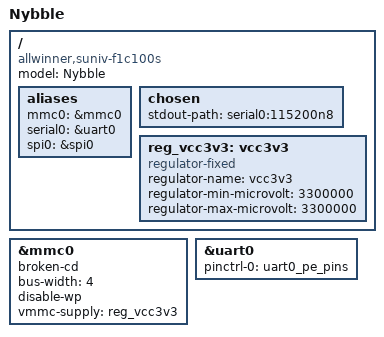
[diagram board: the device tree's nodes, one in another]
/dts-v1/;
#include "suniv-f1c100s.dtsi"

#include <dt-bindings/gpio/gpio.h>

/ {
	model = "Nybble";
	compatible = "allwinner,suniv-f1c100s";

	aliases {
		mmc0 = &mmc0;
		serial0 = &uart0;
		spi0 = &spi0;
	};

	chosen {
		stdout-path = "serial0:115200n8";
	};

	reg_vcc3v3: vcc3v3 {
		compatible = "regulator-fixed";
		regulator-name = "vcc3v3";
		regulator-min-microvolt = <3300000>;
		regulator-max-microvolt = <3300000>;
	};
};

&mmc0 {
	broken-cd;
	bus-width = <4>;
	disable-wp;
	status = "okay";
	vmmc-supply = <&reg_vcc3v3>;
};


&uart0 {
	pinctrl-names = "default";
	pinctrl-0 = <&uart0_pe_pins>;
	status = "okay";
};
